# PIC32MK0512GPE064 device description
Architecture: MIPS; Family: PIC32MK; Series: PIC32MK
Registers are 32-bit, read-write, no defined reset value unless marked. A register's access mark holds for its fields unless they carry their own. Offsets are from the block's base; [hi:lo] are bit positions; {n}, {i} and the like mark numbered series; 'fields as' and 'values as' point back to an identical list; <NAME> marks a mode.

## CAN
Instances: CAN 0x1f880000 in periph_pb5_std
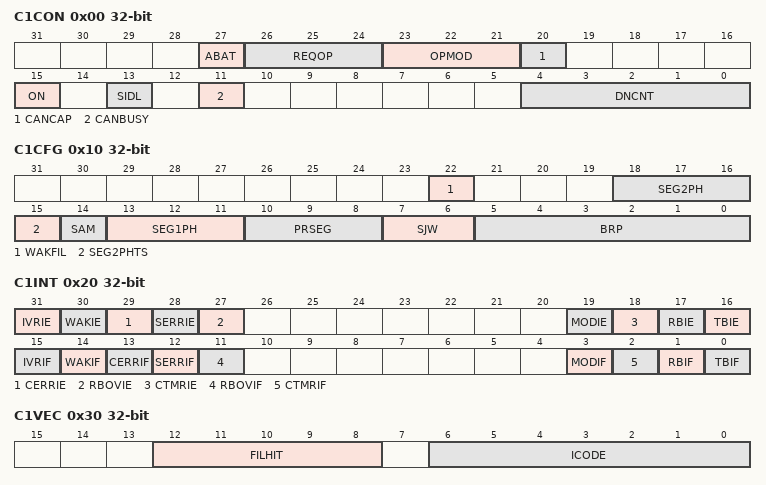
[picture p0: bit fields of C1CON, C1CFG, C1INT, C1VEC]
0x00 C1CON — CAN Module Control Register
  [27] ABAT — Abort All Pending Transmissions bit
    1=Signal all transmit buffers to abort transmission; 0=Module will clear this bit when all transmissions aborted
  [26:24] REQOP — Request Operation Mode bits
    7=Set Listen All Messages mode; 6=Reserved - Do not use; 5=Reserved - Do not use; 4=Set Configuration mode; 3=Set Listen Only mode; 2=Set Loopback mode; 1=Set Disable mode; 0=Set Normal Operation mode
  [23:21] OPMOD — Operation Mode Status bits
    7=Module is in Listen All Messages mode; 4=Module is in Configuration mode; 3=Module is in Listen Only mode; 2=Module is in Loopback mode; 1=Module is in Disable mode; 0=Module is in Normal Operation mode
  [20] CANCAP — CAN Message Receive Time Stamp Timer Capture Enable bit
    16=CANTMR value is stored on valid message reception and is stored with the message; 0=Disable CAN message receive time stamp timer capture and stop CANTMR to conserve power
  [15] ON — CAN On bit
    1=CAN module is enabled; 0=CAN module is disabled
  [13] SIDL — CAN Stop in Idle bit
  [11] CANBUSY — CAN Module is Busy bit
    1=The CAN module is active; 0=The CAN module is completely disabled
  [4:0] DNCNT — Device Net Filter Bit Number bits
    10011-11111=Invalid Selection (compare up to 18-bits of data with EID); 18=Compare up to data byte 2 bit 6 with EID17 (CiRXFn); 1=Compare up to data byte 0 bit 7 with EID0 (CiRXFn); 0=Do not compare data bytes
0x10 C1CFG — CAN Baud Rate Configuration Register
  [22] WAKFIL — CAN Bus Line Filter Enable bit
    1=Use CAN bus line filter for wake-up; 0=CAN bus line filter is not used for wake-up
  [18:16] SEG2PH — Phase Buffer Segment 2 bits
    7=Length is 8 x Tq; 0=Length is 1 x Tq
  [15] SEG2PHTS — Phase Segment 2 Time Select bit
    1=Freely programmable; 0=Maximum of SEG1PH or Information Processing Time
  [14] SAM — Sample of the CAN Bus Line bit
    1=Bus line is sampled three times at the sample point; 0=Bus line is sampled once at the sample point
  [13:11] SEG1PH — Phase Buffer Segment 1 bits
    7=Length is 8 x Tq; 0=Length is 1 x Tq
  [10:8] PRSEG — Propagation Time Segment bits
    7=Length is 8 x Tq; 0=Length is 1 x Tq
  [7:6] SJW — Synchronization Jump Width bits
    {v}=Length is {v+1} x Tq (v=0..3)
  [5:0] BRP — Baud Rate Prescaler bits
    63=Tq = (2 x 64)/Tpbclk5; 62=Tq = (2 x 63)/Tpbclk5; 1=Tq = (2 x 2)/Tpbclk5; 0=Tq = (2 x 1)/Tpbclk5
0x20 C1INT — CAN Interrupt Register
  [31] IVRIE — Invalid Message Received Interrupt Enable bit
    1=Interrupt request is enabled; 0=Interrupt request is not enabled
  [30] WAKIE — CAN Bus Activity Wake-up Interrupt Enable bit
    values as IVRIE
  [29] CERRIE — CAN Bus Error Interrupt Enable bit
    values as IVRIE
  [28] SERRIE — System Error Interrupt Enable bit
    values as IVRIE
  [27] RBOVIE — Receive Buffer Overflow Interrupt Enable bit
    values as IVRIE
  [19] MODIE — Mode Change Interrupt Enable bit
    values as IVRIE
  [18] CTMRIE — CAN Timestamp Timer Interrupt Enable bit
    values as IVRIE
  [17] RBIE — Receive Buffer Interrupt Enable bit
    values as IVRIE
  [16] TBIE — Transmit Buffer Interrupt Enable bit
    values as IVRIE
  [15] IVRIF — Invalid Message Received Interrupt Flag bit
    1=An invalid messages interrupt has occurred; 0=An invalid message interrupt has not occurred
  [14] WAKIF — CAN Bus Activity Wake-up Interrupt Flag bit
    1=A bus wake-up activity interrupt has occurred; 0=A bus wake-up activity interrupt has not occurred
  [13] CERRIF — CAN Bus Error Interrupt Flag bit
    1=A CAN bus error has occurred; 0=A CAN bus error has not occurred
  [12] SERRIF — System Error Interrupt Flag bit
    1=A system error occurred (typically an illegal address was presented to the System Bus); 0=A system error has not occurred
  [11] RBOVIF — Receive Buffer Overflow Interrupt Flag bit
    1=A receive buffer overflow has occurred; 0=A receive buffer overflow has not occurred
  [3] MODIF — CAN Mode Change Interrupt Flag bit
    1=A CAN module mode change has occurred (OPMOD has changed to reflect REQOP); 0=A CAN module mode change has not occurred
  [2] CTMRIF — CAN Timer Overflow Interrupt Flag bit
    1=A CAN timer (CANTMR) overflow has occurred; 0=A CAN timer (CANTMR) overflow has not occurred
  [1] RBIF — Receive Buffer Interrupt Flag bit
    1=A receive buffer interrupt is pending; 0=A receive buffer interrupt is not pending
  [0] TBIF — Transmit Buffer Interrupt Flag bit
    1=A transmit buffer interrupt is pending; 0=A transmit buffer interrupt is not pending
0x30 C1VEC ro — CAN Interrupt Code Register
  [12:8] FILHIT — Filter Hit Number bit
    31=Filter 31; 30=Filter 30; 1=Filter 1; 0=Filter 0
  [6:0] ICODE — Interrupt Flag Code bits
    72=Invalid message received (IVRIF); 71=CAN module mode change (MODIF); 70=CAN timestamp timer (CTMRIF); 69=Bus bandwidth error (SERRIF); 68=Address error interrupt (SERRIF); 67=Receive FIFO overflow interrupt (RBOVIF); 66=Wake-up interrupt (WAKIF); 65=Error Interrupt (CERRIF); 64=No interrupt; 31=FIFO31 Interrupt (CiFSTAT set); 30=FIFO30 Interrupt (CiFSTAT set); 1=FIFO1 Interrupt (CiFSTAT set); 0=FIFO0 Interrupt (CiFSTAT set)
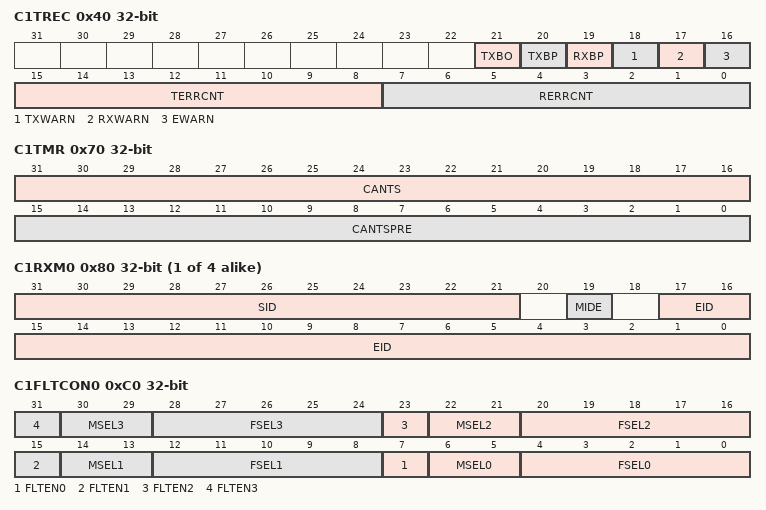
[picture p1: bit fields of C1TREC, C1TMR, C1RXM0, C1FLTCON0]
0x40 C1TREC ro — CAN Transmit/Receive Error Count Register
  [21] TXBO, [20] TXBP, [19] RXBP, [18] TXWARN, [17] RXWARN, [16] EWARN, [15:8] TERRCNT, [7:0] RERRCNT
0x50 C1FSTAT ro — CAN FIFO Status Register
  [31:0] FIFOIP — FIFOx Interrupt Pending bits
    1=One or more enabled FIFO interrupts are pending; 0=No FIFO interrupts are pending
0x60 C1RXOVF ro — CAN Receive FIFO Overflow Status Register
  [31:0] RXOVF — FIFOx Receive Overflow Interrupt Pending bit
    1=FIFO has overflowed; 0=FIFO has not overflowed
0x70 C1TMR — CAN Timer Register
  [31:16] CANTS
  [15:0] CANTSPRE — CAN Time Stamp Timer Prescaler bits
    0xffffffff=CAN time stamp timer (CANTS) increments every 65,535 system clocks; 0=CAN time stamp timer (CANTS) increments every system clock
{0x80+0x10*i} C1RXM{i} (i=0..3) — CAN Acceptance Filter Mask
  [31:21] SID — Standard Identifier bits
    1=Include bit, SIDx, in filter comparison; 0=Bit SIDx is dont care in filter operation
  [19] MIDE — Identifier Receive Mode bit
    1=Match only message types (standard/extended address) that correspond to the EXID bit in filter; 0=Match either standard or extended address message if filters match (that is, if (Filter SID) = (Message SID) or if (FILTER SID/EID) = (Message SID/EID))
  [17:0] EID — Extended Identifier bits
    1=Include bit, EIDx, in filter comparison; 0=Bit EIDx is dont care in filter operation
0xC0 C1FLTCON0 — CAN Filter Control Register 0
  [8n+7] FLTEN{n} (n=0..3) — Filter {n} Enable bit
    1=Filter is enabled; 0=Filter is disabled
  [8n+6:8n+5] MSEL{n} (n=0..3) — Filter {n} Mask Select bits
    {v}=Acceptance Mask {v} selected (v=0..3)
  [8n+4:8n] FSEL{n} (n=0..3) — FIFO Selection bits
    31=Message matching filter is stored in FIFO buffer 31; 30=Message matching filter is stored in FIFO buffer 30; 1=Message matching filter is stored in FIFO buffer 1; 0=Message matching filter is stored in FIFO buffer 0
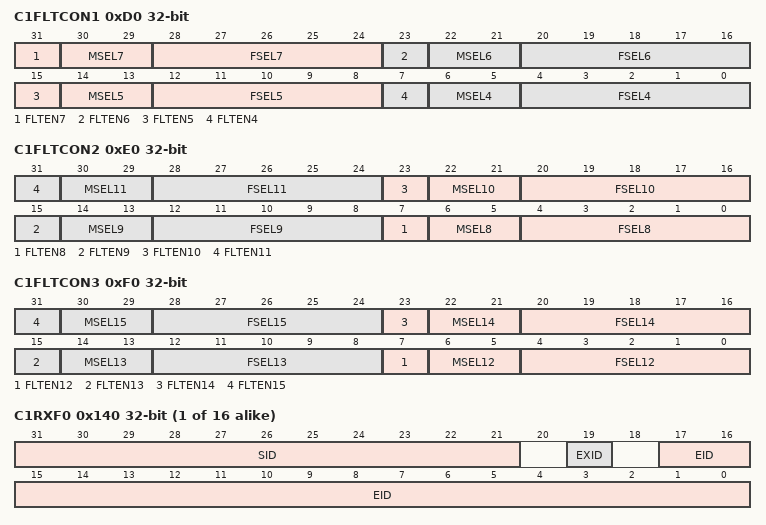
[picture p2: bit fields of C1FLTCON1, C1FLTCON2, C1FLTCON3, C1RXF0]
0xD0 C1FLTCON1 — CAN Filter Control Register 1
  [31] FLTEN7 — Filter 7 Enable bit
    1=Filter is enabled; 0=Filter is disabled
  [8n-26:8n-27] MSEL{n} (n=4..7) — Filter {n} Mask Select bits
    {v}=Acceptance Mask {v} selected (v=0..3)
  [8n-28:8n-32] FSEL{n} (n=4..7) — FIFO Selection bits
    values as C1FLTCON0.FSEL0
  [23] FLTEN6 — Filter 6 Enable bit
    1=Filter is enabled; 0=Filter is disabled
  [15] FLTEN5 — Filter 17 Enable bit
    1=Filter is enabled; 0=Filter is disabled
  [7] FLTEN4 — Filter 4 Enable bit
    1=Filter is enabled; 0=Filter is disabled
0xE0 C1FLTCON2 — CAN Filter Control Register 2
  [8n-57] FLTEN{n} (n=8..11) — Filter {n} Enable bit
    1=Filter is enabled; 0=Filter is disabled
  [8n-58:8n-59] MSEL{n} (n=8..11) — Filter {n} Mask Select bits
    {v}=Acceptance Mask {v} selected (v=0..3)
  [8n-60:8n-64] FSEL{n} (n=8..11) — FIFO Selection bits
    values as C1FLTCON0.FSEL0
0xF0 C1FLTCON3 — CAN Filter Control Register 3
  [8n-89] FLTEN{n} (n=12..15) — Filter {n} Enable bit
    1=Filter is enabled; 0=Filter is disabled
  [8n-90:8n-91] MSEL{n} (n=12..15) — Filter {n} Mask Select bits
    {v}=Acceptance Mask {v} selected (v=0..3)
  [8n-92:8n-96] FSEL{n} (n=12..15) — FIFO Selection bits
    values as C1FLTCON0.FSEL0
{0x140+0x10*i} C1RXF{i} (i=0..15) — CAN Acceptance Filter
  [31:21] SID — Standard Identifier bits
    1=Message address bit SIDx must be 1 to match filter; 0=Message address bit SIDx must be 0 to match filter
  [19] EXID — Extended Identifier Enable bits
    1=Match only messages with extended identifier addresses; 0=Match only messages with standard identifier addresses
  [17:0] EID — Extended Identifier bits
    1=Message address bit EIDx must be 1 to match filter; 0=Message address bit EIDx must be 0 to match filter
0x340 C1FIFOBA — CAN Message Buffer Base Address Register
  [31:2] FIFOBA
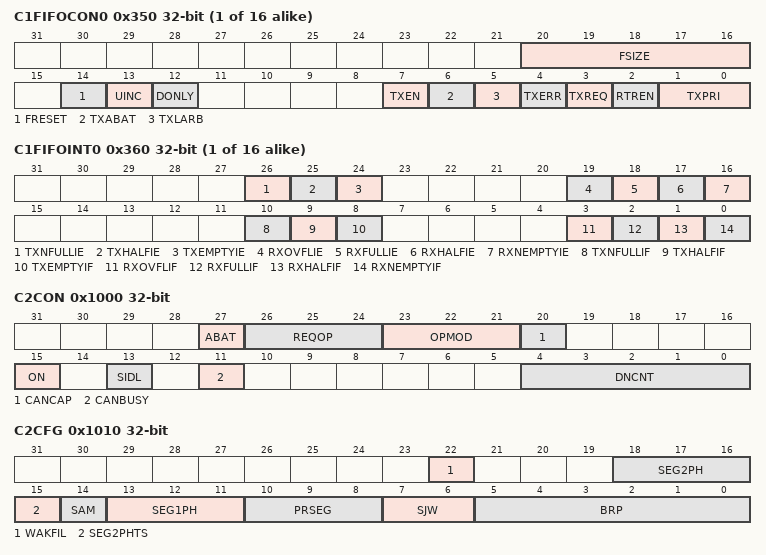
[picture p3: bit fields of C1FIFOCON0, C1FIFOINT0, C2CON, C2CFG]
{0x350+0x40*i} C1FIFOCON{i} (i=0..15) — CAN FIFO Control Register
  [20:16] FSIZE — FIFO Size bits
    31=FIFO is 32 messages deep; 2=FIFO is 3 messages deep; 1=FIFO is 2 messages deep; 0=FIFO is 1 message deep
  [14] FRESET — FIFO Reset bits
    1=FIFO will be reset when bit is set, cleared by hardware when FIFO is reset. After setting, the user application should poll whether this bit is clear before taking any action; 0=No effect
  [13] UINC — Increment Head/Tail bit
    0=1: (FIFO configured as a Transmit FIFO) When this bit is set, the FIFO head will increment by a single message; 0=0: (FIFO configured as a Receive FIFO) When this bit is set, the FIFO tail will increment by a single message
  [12] DONLY — Store Message Data Only bit
    0=1: (FIFO configured as a Transmit FIFO) This bit is not used and has no effect; 0=0: (FIFO configured as a Receive FIFO) 1 = Only data bytes will be stored in the FIFO, 0 = Full message is stored, including identifier
  [7] TXEN — TX/RX Buffer Selection bit
    1=FIFO is a Transmit FIFO; 0=FIFO is a Receive FIFO
  [6] TXABAT — Message Aborted bit
    1=Message was aborted; 0=Message completed successfully
  [5] TXLARB — Message Lost Arbitration bit
    1=Message lost arbitration while being sent; 0=Message did not lose arbitration while being sent
  [4] TXERR — Error Detected During Transmission bit
    1=A bus error occurred while the message was being sent; 0=A bus error did not occur while the message was being sent
  [3] TXREQ — Message Send Request
    0=1: (FIFO configured as a Transmit FIFO) Setting this bit to 1 requests sending a message. The bit will automatically clear when all the messages queued in the FIFO are successfully sent. Clearing the bit to 0 while set will request a message abort.; 0=0: (FIFO configured as a Receive FIFO) This bit has no effect
  [2] RTREN — Auto RTR Enable bit
    1=When a remote transmit is received, TXREQ will be set; 0=When a remote transmit is received, TXREQ will be unaffected
  [1:0] TXPRI — Message Transmit Priority bits
    3=Highest Message Priority; 2=High Intermediate Message Priority; 1=Low Intermediate Message Priority; 0=Lowest Message Priority
{0x360+0x40*i} C1FIFOINT{i} (i=0..15) — CAN FIFO Interrupt Register
  [26] TXNFULLIE — Transmit FIFO Not Full Interrupt Enable bit
    1=Interrupt enabled for FIFO not full; 0=Interrupt disabled for FIFO not full
  [25] TXHALFIE — Transmit FIFO Half Full Interrupt Enable bit
    1=Interrupt enabled for FIFO half full; 0=Interrupt disabled for FIFO half full
  [24] TXEMPTYIE — Transmit FIFO Empty Interrupt Enable bit
    1=Interrupt enabled for FIFO empty; 0=Interrupt disabled for FIFO empty
  [19] RXOVFLIE — Overflow Interrupt Enable bit
    1=Interrupt enabled for overflow event; 0=Interrupt disabled for overflow event
  [18] RXFULLIE — Full Interrupt Enable bit
    1=Interrupt enabled for FIFO full; 0=Interrupt disabled for FIFO full
  [17] RXHALFIE — FIFO Half Full Interrupt Enable bit
    values as TXHALFIE
  [16] RXNEMPTYIE — Empty Interrupt Enable bit
    1=Interrupt enabled for FIFO not empty; 0=Interrupt disabled for FIFO not empty
  [10] TXNFULLIF — Transmit FIFO Not Full Interrupt Flag bit
    0=1: (FIFO configured as a Transmit Buffer) 1 = FIFO is not full, 0 = FIFO is full; 0=0: (FIFO configured as a Receive Buffer) Unused, reads 0
  [9] TXHALFIF — FIFO Transmit FIFO Half Empty Interrupt Flag bit
    0=1: (FIFO configured as a Transmit Buffer) 1 = FIFO is ? half full, 0 = FIFO is > half full; 0=0: (FIFO configured as a Receive Buffer) Unused, reads 0
  [8] TXEMPTYIF — Transmit FIFO Empty Interrupt Flag bit
    0=1: (FIFO configured as a Transmit Buffer) 1 = FIFO is empty, 0 = FIFO is not empty, at least 1 message queued to be transmitted; 0=0: (FIFO configured as a Receive Buffer) Unused, reads 0
  [3] RXOVFLIF — Receive FIFO Overflow Interrupt Flag bit
    0=1: (FIFO configured as a Transmit Buffer) Unused, reads 0; 0=0: (FIFO configured as a Receive Buffer) 1 = Overflow event has occurred, 0 = No overflow event occurred
  [2] RXFULLIF — Receive FIFO Full Interrupt Flag bit
    0=1: (FIFO configured as a Transmit Buffer) Unused, reads 0; 0=0: (FIFO configured as a Receive Buffer) 1 = FIFO is full, 0 = FIFO is not full
  [1] RXHALFIF — Receive FIFO Half Full Interrupt Flag bit
    0=1: (FIFO configured as a Transmit Buffer) Unused, reads 0; 0=0: (FIFO configured as a Receive Buffer) 1 = FIFO is ? half full, 0 = FIFO is < half full
  [0] RXNEMPTYIF — Receive Buffer Not Empty Interrupt Flag bit
    1=1: (FIFO configured as a Transmit Buffer) Unused, reads 0; 0=0: (FIFO configured as a Receive Buffer) 1 = FIFO is not empty, has at least 1 message, 0 = FIFO is empty
{0x370+0x40*i} C1FIFOUA{i} ro (i=0..15) — CAN FIFO User Address Register
  [31:2] FIFOUA
{0x380+0x40*i} C1FIFOCI{i} ro (i=0..15) — CAN Module Message Index Register
  [4:0] CFIFOCI
0x1000 C2CON — CAN Module Control Register
  fields as C1CON
0x1010 C2CFG — CAN Baud Rate Configuration Register
  fields as C1CFG
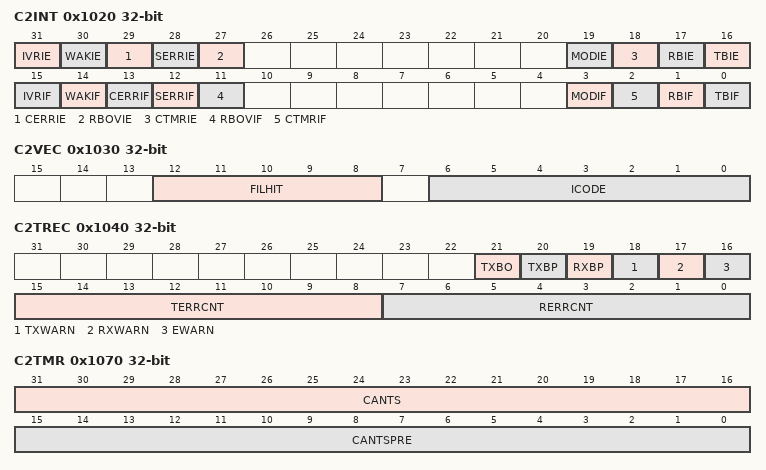
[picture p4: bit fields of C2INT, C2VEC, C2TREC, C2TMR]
0x1020 C2INT — CAN Interrupt Register
  fields as C1INT
0x1030 C2VEC ro — CAN Interrupt Code Register
  fields as C1VEC
0x1040 C2TREC ro — CAN Transmit/Receive Error Count Register
  fields as C1TREC
0x1050 C2FSTAT ro — CAN FIFO Status Register
  fields as C1FSTAT
0x1060 C2RXOVF ro — CAN Receive FIFO Overflow Status Register
  fields as C1RXOVF
0x1070 C2TMR — CAN Timer Register
  fields as C1TMR
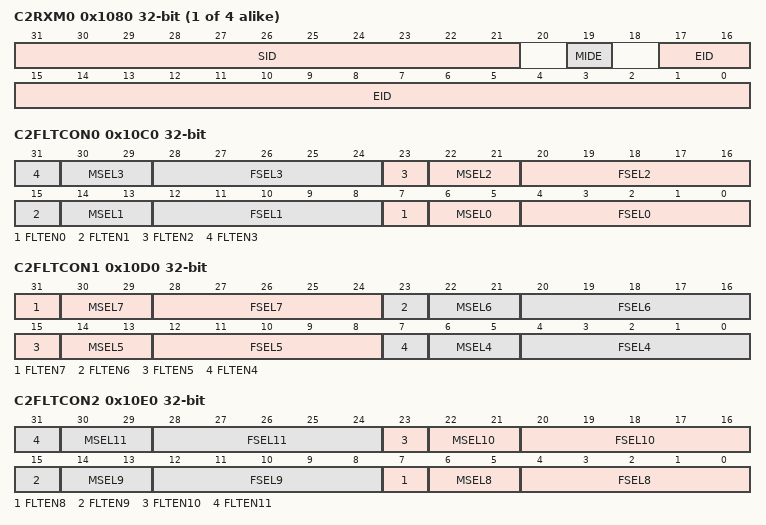
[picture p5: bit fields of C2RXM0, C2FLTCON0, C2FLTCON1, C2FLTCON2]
{0x1080+0x10*i} C2RXM{i} (i=0..3) — CAN Acceptance Filter Mask
  fields as C1RXM0
0x10C0 C2FLTCON0 — CAN Filter Control Register 0
  fields as C1FLTCON0
0x10D0 C2FLTCON1 — CAN Filter Control Register 1
  fields as C1FLTCON1
0x10E0 C2FLTCON2 — CAN Filter Control Register 2
  fields as C1FLTCON2
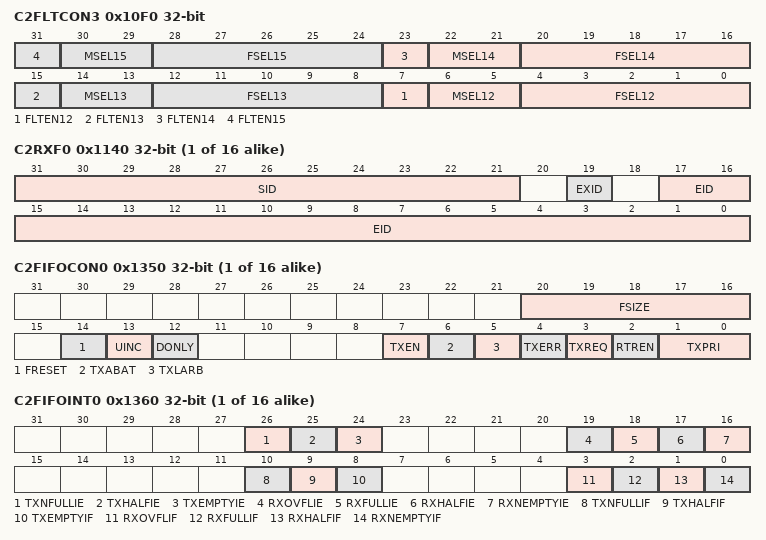
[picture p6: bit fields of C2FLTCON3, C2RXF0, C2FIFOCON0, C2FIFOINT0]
0x10F0 C2FLTCON3 — CAN Filter Control Register 3
  fields as C1FLTCON3
{0x1140+0x10*i} C2RXF{i} (i=0..15) — CAN Acceptance Filter
  fields as C1RXF0
0x1340 C2FIFOBA — CAN Message Buffer Base Address Register
  [31:2] FIFOBA
{0x1350+0x40*i} C2FIFOCON{i} (i=0..15) — CAN FIFO Control Register
  fields as C1FIFOCON0
{0x1360+0x40*i} C2FIFOINT{i} (i=0..15) — CAN FIFO Interrupt Register
  fields as C1FIFOINT0
{0x1370+0x40*i} C2FIFOUA{i} ro (i=0..15) — CAN FIFO User Address Register
  [31:2] FIFOUA
{0x1380+0x40*i} C2FIFOCI{i} ro (i=0..15) — CAN Module Message Index Register
  [4:0] CFIFOCI
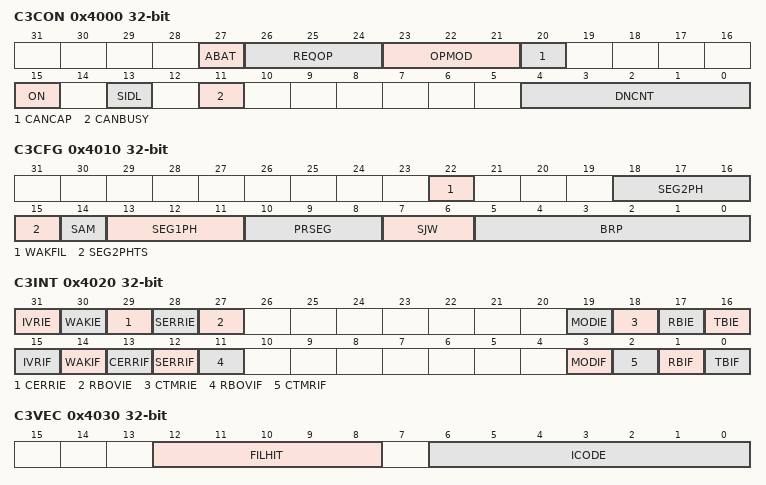
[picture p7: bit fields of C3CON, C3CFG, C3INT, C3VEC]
0x4000 C3CON — CAN Module Control Register
  fields as C1CON
0x4010 C3CFG — CAN Baud Rate Configuration Register
  fields as C1CFG
0x4020 C3INT — CAN Interrupt Register
  fields as C1INT
0x4030 C3VEC ro — CAN Interrupt Code Register
  fields as C1VEC
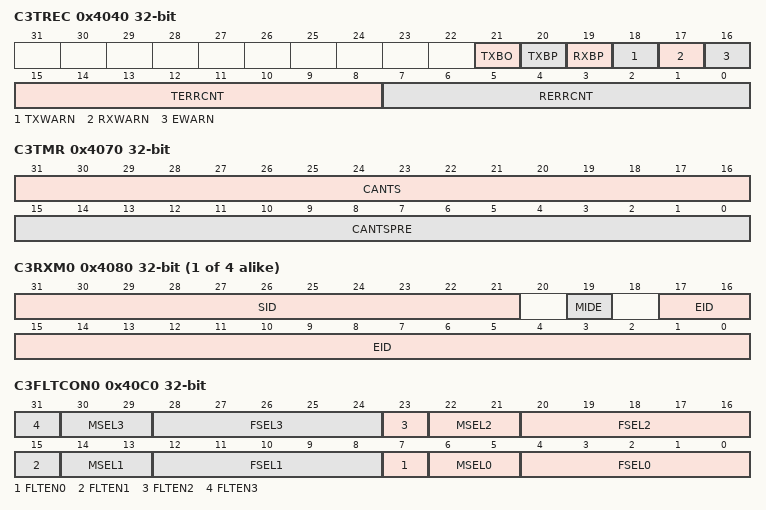
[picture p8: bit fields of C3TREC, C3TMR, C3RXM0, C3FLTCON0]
0x4040 C3TREC ro — CAN Transmit/Receive Error Count Register
  fields as C1TREC
0x4050 C3FSTAT ro — CAN FIFO Status Register
  fields as C1FSTAT
0x4060 C3RXOVF ro — CAN Receive FIFO Overflow Status Register
  fields as C1RXOVF
0x4070 C3TMR — CAN Timer Register
  fields as C1TMR
{0x4080+0x10*i} C3RXM{i} (i=0..3) — CAN Acceptance Filter Mask
  fields as C1RXM0
0x40C0 C3FLTCON0 — CAN Filter Control Register 0
  fields as C1FLTCON0
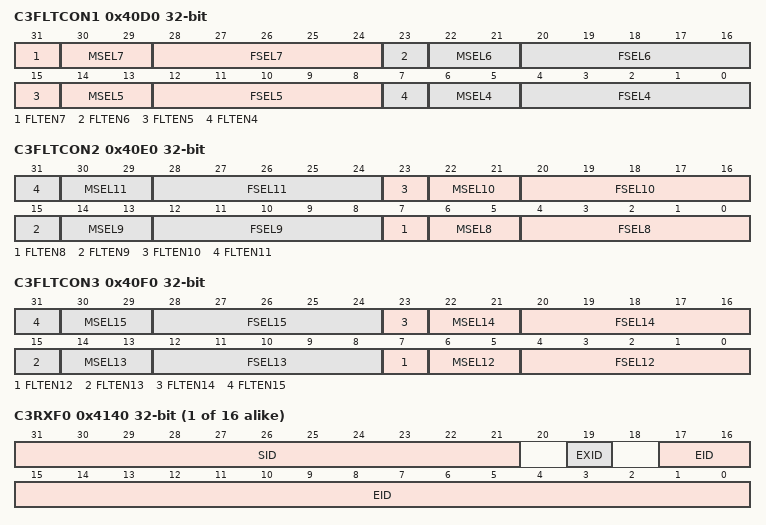
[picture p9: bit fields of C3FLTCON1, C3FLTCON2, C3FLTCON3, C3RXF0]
0x40D0 C3FLTCON1 — CAN Filter Control Register 1
  fields as C1FLTCON1
0x40E0 C3FLTCON2 — CAN Filter Control Register 2
  fields as C1FLTCON2
0x40F0 C3FLTCON3 — CAN Filter Control Register 3
  fields as C1FLTCON3
{0x4140+0x10*i} C3RXF{i} (i=0..15) — CAN Acceptance Filter
  fields as C1RXF0
0x4340 C3FIFOBA — CAN Message Buffer Base Address Register
  [31:2] FIFOBA
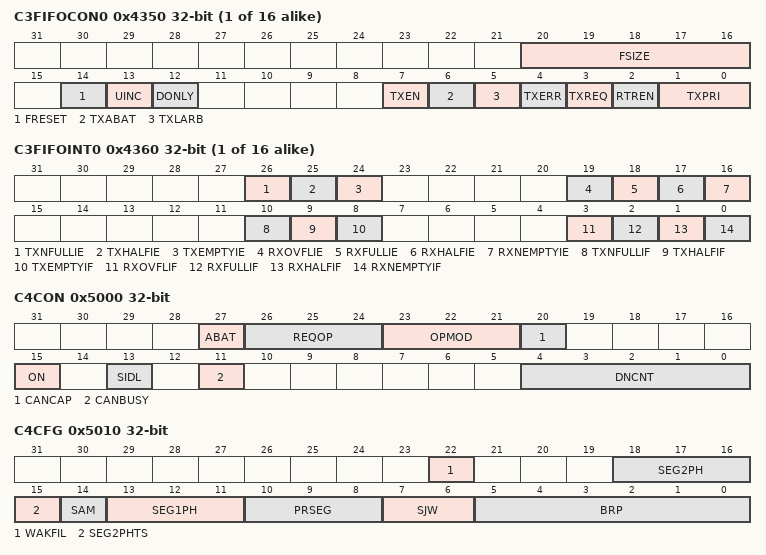
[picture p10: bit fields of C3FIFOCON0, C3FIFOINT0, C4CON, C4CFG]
{0x4350+0x40*i} C3FIFOCON{i} (i=0..15) — CAN FIFO Control Register
  fields as C1FIFOCON0
{0x4360+0x40*i} C3FIFOINT{i} (i=0..15) — CAN FIFO Interrupt Register
  fields as C1FIFOINT0
{0x4370+0x40*i} C3FIFOUA{i} ro (i=0..15) — CAN FIFO User Address Register
  [31:2] FIFOUA
{0x4380+0x40*i} C3FIFOCI{i} ro (i=0..15) — CAN Module Message Index Register
  [4:0] CFIFOCI
0x5000 C4CON — CAN Module Control Register
  fields as C1CON
0x5010 C4CFG — CAN Baud Rate Configuration Register
  fields as C1CFG
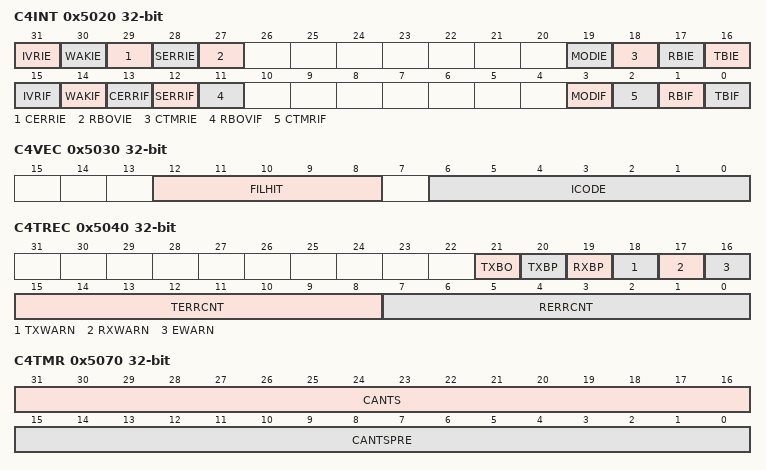
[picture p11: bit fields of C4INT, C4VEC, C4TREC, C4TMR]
0x5020 C4INT — CAN Interrupt Register
  fields as C1INT
0x5030 C4VEC ro — CAN Interrupt Code Register
  fields as C1VEC
0x5040 C4TREC ro — CAN Transmit/Receive Error Count Register
  fields as C1TREC
0x5050 C4FSTAT ro — CAN FIFO Status Register
  fields as C1FSTAT
0x5060 C4RXOVF ro — CAN Receive FIFO Overflow Status Register
  fields as C1RXOVF
0x5070 C4TMR — CAN Timer Register
  fields as C1TMR
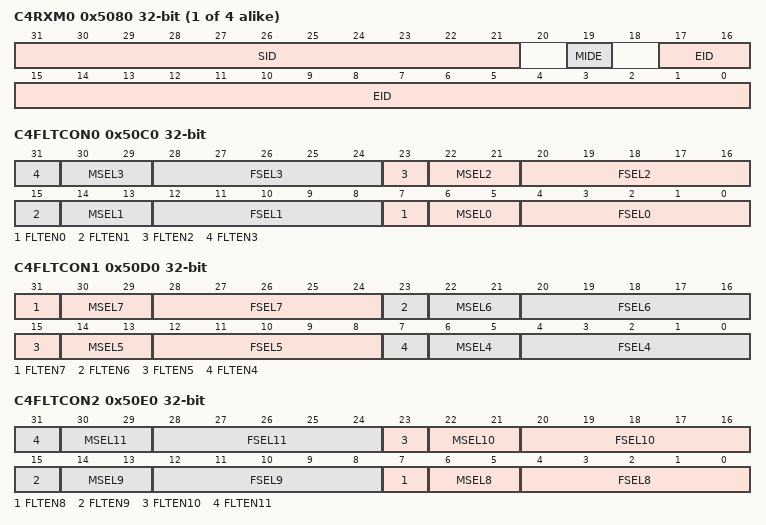
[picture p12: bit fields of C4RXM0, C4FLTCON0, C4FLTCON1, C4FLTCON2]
{0x5080+0x10*i} C4RXM{i} (i=0..3) — CAN Acceptance Filter Mask
  fields as C1RXM0
0x50C0 C4FLTCON0 — CAN Filter Control Register 0
  fields as C1FLTCON0
0x50D0 C4FLTCON1 — CAN Filter Control Register 1
  fields as C1FLTCON1
0x50E0 C4FLTCON2 — CAN Filter Control Register 2
  fields as C1FLTCON2
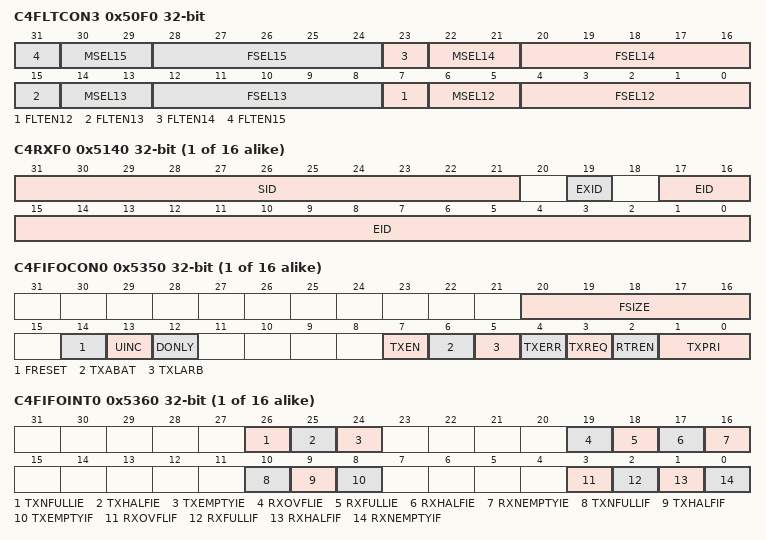
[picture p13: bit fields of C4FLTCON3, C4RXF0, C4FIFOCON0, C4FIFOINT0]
0x50F0 C4FLTCON3 — CAN Filter Control Register 3
  fields as C1FLTCON3
{0x5140+0x10*i} C4RXF{i} (i=0..15) — CAN Acceptance Filter
  fields as C1RXF0
0x5340 C4FIFOBA — CAN Message Buffer Base Address Register
  [31:2] FIFOBA
{0x5350+0x40*i} C4FIFOCON{i} (i=0..15) — CAN FIFO Control Register
  fields as C1FIFOCON0
{0x5360+0x40*i} C4FIFOINT{i} (i=0..15) — CAN FIFO Interrupt Register
  fields as C1FIFOINT0
{0x5370+0x40*i} C4FIFOUA{i} ro (i=0..15) — CAN FIFO User Address Register
  [31:2] FIFOUA
{0x5380+0x40*i} C4FIFOCI{i} ro (i=0..15) — CAN Module Message Index Register
  [4:0] CFIFOCI

## Notices in the file
Copyright (c) 2017 Microchip Technology Inc.
SPDX-License-Identifier: Apache-2.0
Licensed under the Apache License, Version 2.0 (the "License");
you may not use this file except in compliance with the License.
You may obtain a copy of the License at
http://www.apache.org/licenses/LICENSE-2.0
Unless required by applicable law or agreed to in writing, software
distributed under the License is distributed on an "AS IS" BASIS,
WITHOUT WARRANTIES OR CONDITIONS OF ANY KIND, either express or implied.
See the License for the specific language governing permissions and
limitations under the License.
